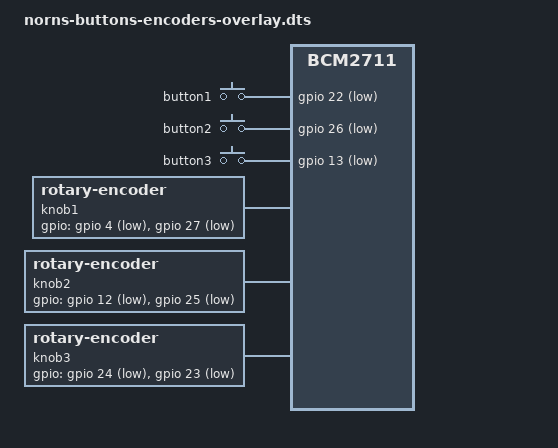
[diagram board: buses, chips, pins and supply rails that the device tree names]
// SPDX-License-Identifier: GPL-2.0
/*
 * norns shield keys and encoders, for the Raspberry Pi 4.
 *
 * Derived from monome/linux branch norns-5.10.y,
 * arch/arm/boot/dts/overlays/norns-buttons-encoders-overlay.dts (GPL-2.0).
 * Changes from monome's overlay:
 *  - compatible: brcm,bcm2711 (Pi 4) instead of brcm,bcm2835/2708/2709.
 *  - The defaults are the shield's pins (E1 4/27, E2 12/25, E3 24/23,
 *    K1 22, K2 26, K3 13), which monome set with dtparams in
 *    platform/shield/config.txt; monome's defaults were the CM3 norns'
 *    pins. The same parameters still override them.
 *  - The pin groups are added to the GPIO controller through &gpio rather
 *    than target-path "/soc/gpio" (the node is /soc/gpio@7e200000).
 *  - rotary-encoder,steps-per-period = <2> replaces the deprecated
 *    rotary-encoder,half-period (the driver treats them the same).
 *  - #address-cells/#size-cells are dropped from the encoder and keys
 *    nodes, which have no addressed children.
 * Node names are kept: matron opens /dev/input/by-path/platform-soc:knobN-event
 * (knobN directly under /soc) and platform-keys-event (keys under /).
 */
/dts-v1/;
/plugin/;

/ {
	compatible = "brcm,bcm2711";

	fragment@0 {
		target = <&gpio>;
		__overlay__ {
			knob_pins1: knob_pins1 {
				brcm,pins = <4 27>;
				brcm,function = <0>;
				brcm,pull = <2>;
			};
		};
	};

	fragment@1 {
		target-path = "/soc";
		__overlay__ {
			knob1: knob1 {
				compatible = "rotary-encoder";
				pinctrl-names = "default";
				pinctrl-0 = <&knob_pins1>;
				gpios = <&gpio 4 1>, <&gpio 27 1>;
				linux,axis = <0>; /* REL_X */
				rotary-encoder,relative-axis;
				rotary-encoder,steps-per-period = <2>;
			};
		};
	};

	fragment@2 {
		target = <&gpio>;
		__overlay__ {
			knob_pins2: knob_pins2 {
				brcm,pins = <12 25>;
				brcm,function = <0>;
				brcm,pull = <2>;
			};
		};
	};

	fragment@3 {
		target-path = "/soc";
		__overlay__ {
			knob2: knob2 {
				compatible = "rotary-encoder";
				pinctrl-names = "default";
				pinctrl-0 = <&knob_pins2>;
				gpios = <&gpio 12 1>, <&gpio 25 1>;
				linux,axis = <0>; /* REL_X */
				rotary-encoder,relative-axis;
				rotary-encoder,steps-per-period = <2>;
			};
		};
	};

	fragment@4 {
		target = <&gpio>;
		__overlay__ {
			knob_pins3: knob_pins3 {
				brcm,pins = <24 23>;
				brcm,function = <0>;
				brcm,pull = <2>;
			};
		};
	};

	fragment@5 {
		target-path = "/soc";
		__overlay__ {
			knob3: knob3 {
				compatible = "rotary-encoder";
				pinctrl-names = "default";
				pinctrl-0 = <&knob_pins3>;
				gpios = <&gpio 24 1>, <&gpio 23 1>;
				linux,axis = <0>; /* REL_X */
				rotary-encoder,relative-axis;
				rotary-encoder,steps-per-period = <2>;
			};
		};
	};

	fragment@6 {
		target-path = "/";
		__overlay__ {
			keypad: keys {
				compatible = "gpio-keys";
				button1: button1 {
					linux,code = <1>; /* KEY_ESC */
					gpios = <&gpio 22 1>;
				};
				button2: button2 {
					linux,code = <2>; /* KEY_1 */
					gpios = <&gpio 26 1>;
				};
				button3: button3 {
					linux,code = <3>; /* KEY_2 */
					gpios = <&gpio 13 1>;
				};
			};
		};
	};

	__overrides__ {
		e1_pin_a = <&knob_pins1>,"brcm,pins:0",
			   <&knob1>,"gpios:4";
		e1_pin_b = <&knob_pins1>,"brcm,pins:4",
			   <&knob1>,"gpios:16";
		e2_pin_a = <&knob_pins2>,"brcm,pins:0",
			   <&knob2>,"gpios:4";
		e2_pin_b = <&knob_pins2>,"brcm,pins:4",
			   <&knob2>,"gpios:16";
		e3_pin_a = <&knob_pins3>,"brcm,pins:0",
			   <&knob3>,"gpios:4";
		e3_pin_b = <&knob_pins3>,"brcm,pins:4",
			   <&knob3>,"gpios:16";
		b1_pin = <&button1>,"gpios:4";
		b2_pin = <&button2>,"gpios:4";
		b3_pin = <&button3>,"gpios:4";
	};
};
